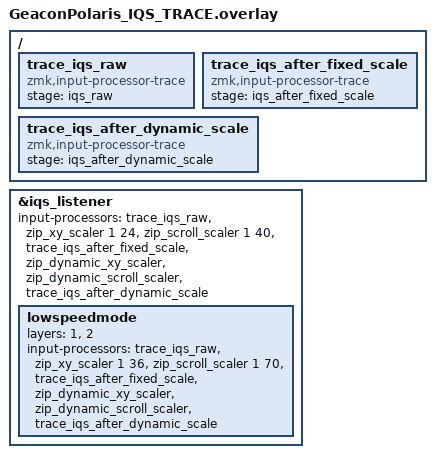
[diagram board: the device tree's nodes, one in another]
/*
 * Example trace overlay for te9no/zmk-config-GeaconPolaris snippets/IQS.
 *
 * It samples the Azoteq IQS listener before scaling, after fixed scaling,
 * and after dynamic scaling.
 */

/ {
    trace_iqs_raw: trace_iqs_raw {
        compatible = "zmk,input-processor-trace";
        stage = "iqs_raw";
        #input-processor-cells = <0>;
    };

    trace_iqs_after_fixed_scale: trace_iqs_after_fixed_scale {
        compatible = "zmk,input-processor-trace";
        stage = "iqs_after_fixed_scale";
        #input-processor-cells = <0>;
    };

    trace_iqs_after_dynamic_scale: trace_iqs_after_dynamic_scale {
        compatible = "zmk,input-processor-trace";
        stage = "iqs_after_dynamic_scale";
        #input-processor-cells = <0>;
    };
};

&iqs_listener {
    input-processors = <&trace_iqs_raw>,
                       <&zip_xy_scaler 1 24>,
                       <&zip_scroll_scaler 1 40>,
                       <&trace_iqs_after_fixed_scale>,
                       <&zip_dynamic_xy_scaler>,
                       <&zip_dynamic_scroll_scaler>,
                       <&trace_iqs_after_dynamic_scale>;

    lowspeedmode {
        layers = <1>, <2>;
        input-processors = <&trace_iqs_raw>,
                           <&zip_xy_scaler 1 36>,
                           <&zip_scroll_scaler 1 70>,
                           <&trace_iqs_after_fixed_scale>,
                           <&zip_dynamic_xy_scaler>,
                           <&zip_dynamic_scroll_scaler>,
                           <&trace_iqs_after_dynamic_scale>;
    };
};
